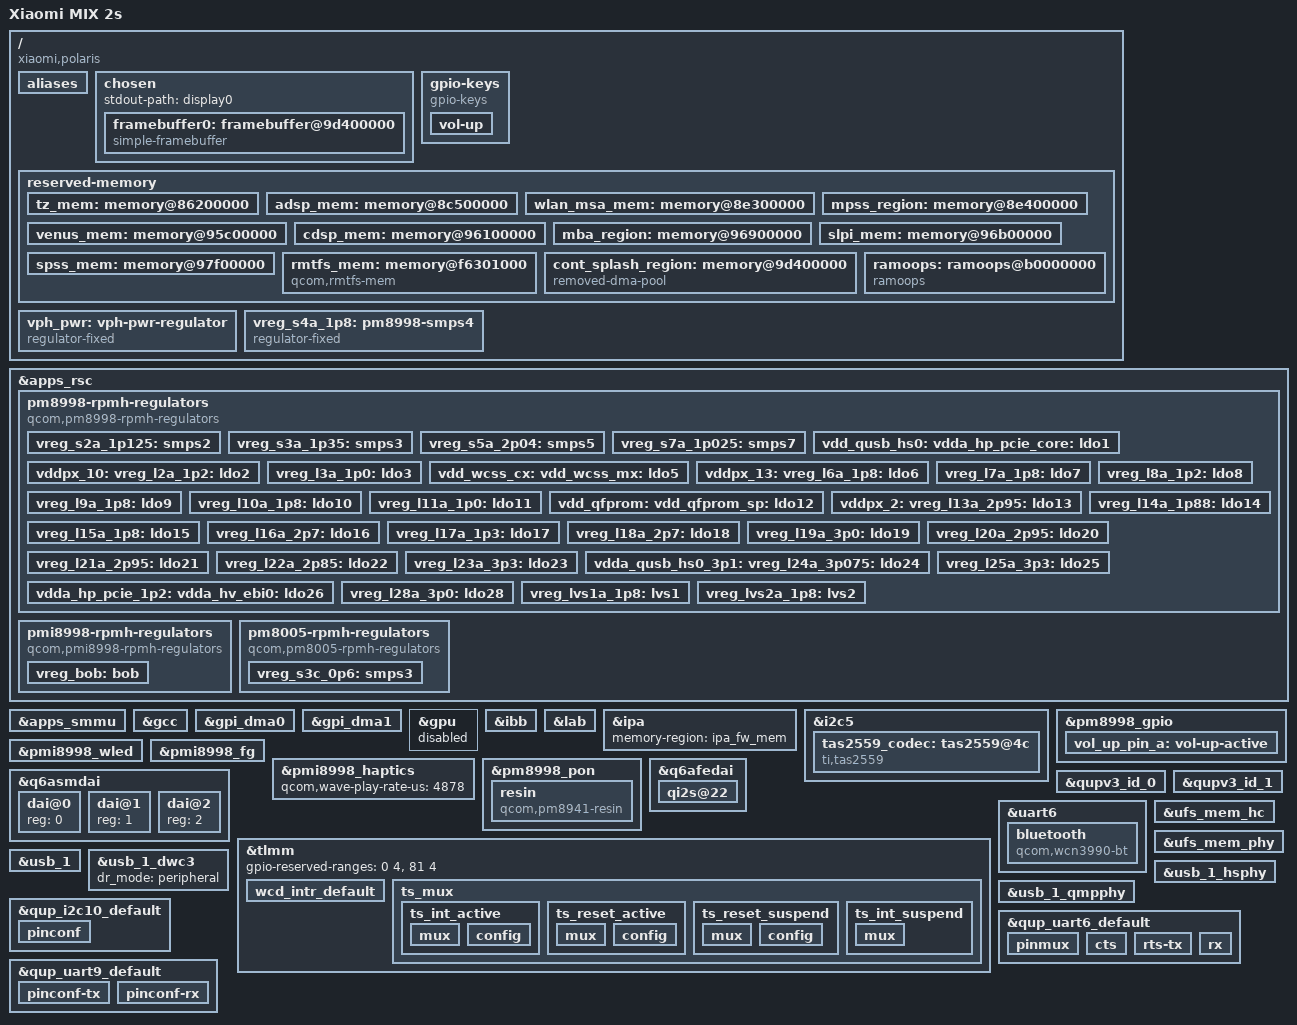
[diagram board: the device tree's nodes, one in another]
// SPDX-License-Identifier: GPL-2.0
/*
	SDM845 Xiaomi MIX 2s (polaris) device tree
*/

/dts-v1/;

#include <dt-bindings/dma/qcom-gpi.h>
#include <dt-bindings/gpio/gpio.h>
#include <dt-bindings/pinctrl/qcom,pmic-gpio.h>
#include <dt-bindings/regulator/qcom,rpmh-regulator.h>
#include <dt-bindings/sound/qcom,q6afe.h>
#include <dt-bindings/sound/qcom,q6asm.h>
#include "sdm845.dtsi"
#include "pm8998.dtsi"
#include "pmi8998.dtsi"

/*
 * Delete following upstream (sdm845.dtsi) reserved
 * memory mappings which are different in this device.
 */
/delete-node/ &tz_mem;
/delete-node/ &adsp_mem;
/delete-node/ &wlan_msa_mem;
/delete-node/ &mpss_region;
/delete-node/ &venus_mem;
/delete-node/ &cdsp_mem;
/delete-node/ &mba_region;
/delete-node/ &slpi_mem;
/delete-node/ &spss_mem;
/delete-node/ &rmtfs_mem;

/delete-node/ &cdsp_pas;
/delete-node/ &dsi0;
/delete-node/ &dsi0_phy;
/delete-node/ &dsi1;
/delete-node/ &dsi1_phy;
/delete-node/ &mdss;
/delete-node/ &mss_pil;
/delete-node/ &sdhc_2;

/delete-node/ &dispcc;

/ {
	model = "Xiaomi MIX 2s";
	compatible = "xiaomi,polaris", "qcom,sdm845";

	/* required for bootloader to select correct board */
	qcom,board-id = <0x2a 0x0>;
	qcom,msm-id = <0x141 0x20001>;

	aliases {
		serial0 = &uart9;
		hsuart0 = &uart6;
	};

	chosen {
		#address-cells = <2>;
		#size-cells = <2>;
		ranges;

		// For simplefb hack
		stdout-path = "display0";
		
		/* hack: use framebuffer setup by bootloader.
		 * the address is taken from the bootloader config (strings xbl.img | grep "Display Reserved")
		 */
		framebuffer0: framebuffer@9d400000 {
			compatible = "simple-framebuffer";
			reg = <0 0x9D400000 0 0x02400000>;
			width = <1080>;
			height = <2160>;
			stride = <(1080 * 4)>;
			format = "a8r8g8b8";
			status = "okay";
		};
	};

	gpio-keys {
		compatible = "gpio-keys";
		autorepeat;

		pinctrl-names = "default";
		pinctrl-0 = <&vol_up_pin_a>;

		vol-up {
			label = "Volume Up";
			linux,code = <KEY_VOLUMEUP>;
			gpios = <&pm8998_gpio 6 GPIO_ACTIVE_LOW>;
		};
	};

	/* Reserved memory changes from downstream */
	reserved-memory {
		tz_mem: memory@86200000 {
			reg = <0 0x86200000 0 0x4900000>;
			no-map;
		};

		adsp_mem: memory@8c500000 {
			reg = <0 0x8c500000 0 0x1e00000>;
			no-map;
		};

		wlan_msa_mem: memory@8e300000 {
			reg = <0 0x8e300000 0 0x100000>;
			no-map;
		};

		mpss_region: memory@8e400000 {
			reg = <0 0x8e400000 0 0x7800000>;
			no-map;
		};

		venus_mem: memory@95c00000 {
			reg = <0 0x95c00000 0 0x500000>;
			no-map;
		};

		cdsp_mem: memory@96100000 {
			reg = <0 0x96100000 0 0x800000>;
			no-map;
		};

		mba_region: memory@96900000 {
			reg = <0 0x96900000 0 0x200000>;
			no-map;
		};

		slpi_mem: memory@96b00000 {
			reg = <0 0x96b00000 0 0x1400000>;
			no-map;
		};

		spss_mem: memory@97f00000 {
			reg = <0 0x97f00000 0 0x100000>;
			no-map;
		};

		rmtfs_mem: memory@f6301000 {
			compatible = "qcom,rmtfs-mem";
			reg = <0 0xf6301000 0 0x200000>;
			no-map;

			qcom,client-id = <1>;
			qcom,vmid = <15>;
		};

		/* hack: bootloader framebuffer */
		cont_splash_region: memory@9d400000 {
			compatible = "removed-dma-pool";
			reg = <0 0x9D400000 0 0x02400000>;
			no-map;
		};

		ramoops: ramoops@b0000000 {
			compatible = "ramoops";
			reg = <0 0xb0000000 0 0x00400000>;
			record-size = <0x40000>; /*256x1024*/
			console-size = <0x40000>;
			ftrace-size = <0x40000>;
			pmsg-size = <0x200000>;
			ecc-size = <0x0>;
		};
	};

	vph_pwr: vph-pwr-regulator {
		compatible = "regulator-fixed";
		regulator-name = "vph_pwr";
		regulator-min-microvolt = <3700000>;
		regulator-max-microvolt = <3700000>;
	};

	/*
	 * Apparently RPMh does not provide support for PM8998 S4 because it
	 * is always-on; model it as a fixed regulator.
	 */
	vreg_s4a_1p8: pm8998-smps4 {
		compatible = "regulator-fixed";
		regulator-name = "vreg_s4a_1p8";

		regulator-min-microvolt = <1800000>;
		regulator-max-microvolt = <1800000>;

		regulator-always-on;
		regulator-boot-on;

		vin-supply = <&vph_pwr>;
	};
};

&apps_rsc {
	pm8998-rpmh-regulators {
		compatible = "qcom,pm8998-rpmh-regulators";
		qcom,pmic-id = "a";

		vdd-s1-supply = <&vph_pwr>;
		vdd-s2-supply = <&vph_pwr>;
		vdd-s3-supply = <&vph_pwr>;
		vdd-s4-supply = <&vph_pwr>;
		vdd-s5-supply = <&vph_pwr>;
		vdd-s6-supply = <&vph_pwr>;
		vdd-s7-supply = <&vph_pwr>;
		vdd-s8-supply = <&vph_pwr>;
		vdd-s9-supply = <&vph_pwr>;
		vdd-s10-supply = <&vph_pwr>;
		vdd-s11-supply = <&vph_pwr>;
		vdd-s12-supply = <&vph_pwr>;
		vdd-s13-supply = <&vph_pwr>;
		vdd-l1-l27-supply = <&vreg_s7a_1p025>;
		vdd-l2-l8-l17-supply = <&vreg_s3a_1p35>;
		vdd-l3-l11-supply = <&vreg_s7a_1p025>;
		vdd-l4-l5-supply = <&vreg_s7a_1p025>;
		vdd-l6-supply = <&vph_pwr>;
		vdd-l7-l12-l14-l15-supply = <&vreg_s5a_2p04>;
		vdd-l9-supply = <&vreg_bob>;
		vdd-l10-l23-l25-supply = <&vreg_bob>;
		vdd-l13-l19-l21-supply = <&vreg_bob>;
		vdd-l16-l28-supply = <&vreg_bob>;
		vdd-l18-l22-supply = <&vreg_bob>;
		vdd-l20-l24-supply = <&vreg_bob>;
		vdd-l26-supply = <&vreg_s3a_1p35>;
		vin-lvs-1-2-supply = <&vreg_s4a_1p8>;

		vreg_s2a_1p125: smps2 {
			regulator-min-microvolt = <1100000>;
			regulator-max-microvolt = <1100000>;
		};

		vreg_s3a_1p35: smps3 {
			regulator-min-microvolt = <1352000>;
			regulator-max-microvolt = <1352000>;
		};

		vreg_s5a_2p04: smps5 {
			regulator-min-microvolt = <1904000>;
			regulator-max-microvolt = <2040000>;
		};

		vreg_s7a_1p025: smps7 {
			regulator-min-microvolt = <900000>;
			regulator-max-microvolt = <1028000>;
		};

		vdd_qusb_hs0:
		vdda_hp_pcie_core:
		vdda_mipi_csi0_0p9:
		vdda_mipi_csi1_0p9:
		vdda_mipi_csi2_0p9:
		vdda_mipi_dsi0_pll:
		vdda_mipi_dsi1_pll:
		vdda_qlink_lv:
		vdda_qlink_lv_ck:
		vdda_qrefs_0p875:
		vdda_pcie_core:
		vdda_pll_cc_ebi01:
		vdda_pll_cc_ebi23:
		vdda_sp_sensor:
		vdda_ufs1_core:
		vdda_ufs2_core:
		vdda_usb1_ss_core:
		vdda_usb2_ss_core:
		vreg_l1a_0p875: ldo1 {
			regulator-min-microvolt = <880000>;
			regulator-max-microvolt = <880000>;
			regulator-initial-mode = <RPMH_REGULATOR_MODE_HPM>;
		};

		vddpx_10:
		vreg_l2a_1p2: ldo2 {
			regulator-min-microvolt = <1200000>;
			regulator-max-microvolt = <1200000>;
			regulator-initial-mode = <RPMH_REGULATOR_MODE_HPM>;
			regulator-always-on;
		};

		vreg_l3a_1p0: ldo3 {
			regulator-min-microvolt = <1000000>;
			regulator-max-microvolt = <1000000>;
			regulator-initial-mode = <RPMH_REGULATOR_MODE_HPM>;
		};

		vdd_wcss_cx:
		vdd_wcss_mx:
		vdda_wcss_pll:
		vreg_l5a_0p8: ldo5 {
			regulator-min-microvolt = <800000>;
			regulator-max-microvolt = <800000>;
			regulator-initial-mode = <RPMH_REGULATOR_MODE_HPM>;
		};

		vddpx_13:
		vreg_l6a_1p8: ldo6 {
			regulator-min-microvolt = <1856000>;
			regulator-max-microvolt = <1856000>;
			regulator-initial-mode = <RPMH_REGULATOR_MODE_HPM>;
		};

		vreg_l7a_1p8: ldo7 {
			regulator-min-microvolt = <1800000>;
			regulator-max-microvolt = <1800000>;
			regulator-initial-mode = <RPMH_REGULATOR_MODE_HPM>;
		};

		vreg_l8a_1p2: ldo8 {
			regulator-min-microvolt = <1200000>;
			regulator-max-microvolt = <1248000>;
			regulator-initial-mode = <RPMH_REGULATOR_MODE_HPM>;
		};

		vreg_l9a_1p8: ldo9 {
			regulator-min-microvolt = <1704000>;
			regulator-max-microvolt = <2928000>;
			regulator-initial-mode = <RPMH_REGULATOR_MODE_HPM>;
		};

		vreg_l10a_1p8: ldo10 {
			regulator-min-microvolt = <1704000>;
			regulator-max-microvolt = <2928000>;
			regulator-initial-mode = <RPMH_REGULATOR_MODE_HPM>;
		};

		vreg_l11a_1p0: ldo11 {
			regulator-min-microvolt = <1000000>;
			regulator-max-microvolt = <1048000>;
			regulator-initial-mode = <RPMH_REGULATOR_MODE_HPM>;
		};

		vdd_qfprom:
		vdd_qfprom_sp:
		vdda_apc1_cs_1p8:
		vdda_gfx_cs_1p8:
		vdda_qrefs_1p8:
		vdda_qusb_hs0_1p8:
		vddpx_11:
		vreg_l12a_1p8: ldo12 {
			regulator-min-microvolt = <1800000>;
			regulator-max-microvolt = <1800000>;
			regulator-initial-mode = <RPMH_REGULATOR_MODE_HPM>;
		};

		vddpx_2:
		vreg_l13a_2p95: ldo13 {
			regulator-min-microvolt = <1800000>;
			regulator-max-microvolt = <2960000>;
			regulator-initial-mode = <RPMH_REGULATOR_MODE_HPM>;
		};

		vreg_l14a_1p88: ldo14 {
			regulator-min-microvolt = <1800000>;
			regulator-max-microvolt = <1800000>;
			regulator-initial-mode = <RPMH_REGULATOR_MODE_HPM>;
		};

		vreg_l15a_1p8: ldo15 {
			regulator-min-microvolt = <1800000>;
			regulator-max-microvolt = <1800000>;
			regulator-initial-mode = <RPMH_REGULATOR_MODE_HPM>;
		};

		vreg_l16a_2p7: ldo16 {
			regulator-min-microvolt = <2704000>;
			regulator-max-microvolt = <2704000>;
			regulator-initial-mode = <RPMH_REGULATOR_MODE_HPM>;
		};

		vreg_l17a_1p3: ldo17 {
			regulator-min-microvolt = <1304000>;
			regulator-max-microvolt = <1304000>;
			regulator-initial-mode = <RPMH_REGULATOR_MODE_HPM>;
		};

		vreg_l18a_2p7: ldo18 {
			regulator-min-microvolt = <2704000>;
			regulator-max-microvolt = <2960000>;
			regulator-initial-mode = <RPMH_REGULATOR_MODE_HPM>;
		};

		vreg_l19a_3p0: ldo19 {
			regulator-min-microvolt = <2856000>;
			regulator-max-microvolt = <3104000>;
			regulator-initial-mode = <RPMH_REGULATOR_MODE_HPM>;
		};

		vreg_l20a_2p95: ldo20 {
			regulator-min-microvolt = <2704000>;
			regulator-max-microvolt = <2960000>;
			regulator-initial-mode = <RPMH_REGULATOR_MODE_HPM>;
		};

		vreg_l21a_2p95: ldo21 {
			regulator-min-microvolt = <2704000>;
			regulator-max-microvolt = <2960000>;
			regulator-initial-mode = <RPMH_REGULATOR_MODE_HPM>;
		};

		vreg_l22a_2p85: ldo22 {
			regulator-min-microvolt = <2864000>;
			regulator-max-microvolt = <3312000>;
			regulator-initial-mode = <RPMH_REGULATOR_MODE_HPM>;
		};

		vreg_l23a_3p3: ldo23 {
			regulator-min-microvolt = <3000000>;
			regulator-max-microvolt = <3312000>;
			regulator-initial-mode = <RPMH_REGULATOR_MODE_HPM>;
		};

		vdda_qusb_hs0_3p1:
		vreg_l24a_3p075: ldo24 {
			regulator-min-microvolt = <3088000>;
			regulator-max-microvolt = <3088000>;
			regulator-initial-mode = <RPMH_REGULATOR_MODE_HPM>;
		};

		vreg_l25a_3p3: ldo25 {
			regulator-min-microvolt = <3300000>;
			regulator-max-microvolt = <3312000>;
			regulator-initial-mode = <RPMH_REGULATOR_MODE_HPM>;
		};

		vdda_hp_pcie_1p2:
		vdda_hv_ebi0:
		vdda_hv_ebi1:
		vdda_hv_ebi2:
		vdda_hv_ebi3:
		vdda_mipi_csi_1p25:
		vdda_mipi_dsi0_1p2:
		vdda_mipi_dsi1_1p2:
		vdda_pcie_1p2:
		vdda_ufs1_1p2:
		vdda_ufs2_1p2:
		vdda_usb1_ss_1p2:
		vdda_usb2_ss_1p2:
		vreg_l26a_1p2: ldo26 {
			regulator-min-microvolt = <1200000>;
			regulator-max-microvolt = <1200000>;
			regulator-initial-mode = <RPMH_REGULATOR_MODE_HPM>;
		};

		vreg_l28a_3p0: ldo28 {
			regulator-min-microvolt = <2856000>;
			regulator-max-microvolt = <3008000>;
			regulator-initial-mode = <RPMH_REGULATOR_MODE_HPM>;
		};

		vreg_lvs1a_1p8: lvs1 {
			regulator-min-microvolt = <1800000>;
			regulator-max-microvolt = <1800000>;
		};

		vreg_lvs2a_1p8: lvs2 {
			regulator-min-microvolt = <1800000>;
			regulator-max-microvolt = <1800000>;
		};
	};

	pmi8998-rpmh-regulators {
		compatible = "qcom,pmi8998-rpmh-regulators";
		qcom,pmic-id = "b";

		vdd-bob-supply = <&vph_pwr>;

		vreg_bob: bob {
			regulator-min-microvolt = <3312000>;
			regulator-max-microvolt = <3600000>;
			regulator-initial-mode = <RPMH_REGULATOR_MODE_AUTO>;
			regulator-allow-bypass;
		};
	};

	pm8005-rpmh-regulators {
		compatible = "qcom,pm8005-rpmh-regulators";
		qcom,pmic-id = "c";

		vdd-s1-supply = <&vph_pwr>;
		vdd-s2-supply = <&vph_pwr>;
		vdd-s3-supply = <&vph_pwr>;
		vdd-s4-supply = <&vph_pwr>;

		vreg_s3c_0p6: smps3 {
			regulator-min-microvolt = <600000>;
			regulator-max-microvolt = <600000>;
		};
	};
};

/*
&apps_rsc {
	pm8998-rpmh-regulators {
		compatible = "qcom,pm8998-rpmh-regulators";
		qcom,pmic-id = "a";

		vreg_l1a_0p875: ldo1 {
			regulator-min-microvolt = <880000>;
			regulator-max-microvolt = <880000>;
			regulator-initial-mode = <RPMH_REGULATOR_MODE_HPM>;
		};

		vreg_l5a_0p8: ldo5 {
			regulator-min-microvolt = <800000>;
			regulator-max-microvolt = <800000>;
			regulator-initial-mode = <RPMH_REGULATOR_MODE_HPM>;
		};

		vreg_l7a_1p8: ldo7 {
			regulator-min-microvolt = <1800000>;
			regulator-max-microvolt = <1800000>;
			regulator-initial-mode = <RPMH_REGULATOR_MODE_HPM>;
		};

		vreg_l12a_1p8: ldo12 {
			regulator-min-microvolt = <1800000>;
			regulator-max-microvolt = <1800000>;
			regulator-initial-mode = <RPMH_REGULATOR_MODE_HPM>;
		};

		vreg_l13a_2p95: ldo13 {
			regulator-min-microvolt = <1800000>;
			regulator-max-microvolt = <2960000>;
			regulator-initial-mode = <RPMH_REGULATOR_MODE_HPM>;
		};

		vreg_l14a_1p8: ldo14 {
			regulator-min-microvolt = <1800000>;
			regulator-max-microvolt = <1800000>;
			regulator-initial-mode = <RPMH_REGULATOR_MODE_HPM>;
			regulator-boot-on;
			regulator-always-on;
		};

		vreg_l17a_1p3: ldo17 {
			regulator-min-microvolt = <1304000>;
			regulator-max-microvolt = <1304000>;
			regulator-initial-mode = <RPMH_REGULATOR_MODE_HPM>;
		};

		vreg_l20a_2p95: ldo20 {
			regulator-min-microvolt = <2960000>;
			regulator-max-microvolt = <2968000>;
			regulator-initial-mode = <RPMH_REGULATOR_MODE_HPM>;
		};

		vreg_l21a_2p95: ldo21 {
			regulator-min-microvolt = <2960000>;
			regulator-max-microvolt = <2968000>;
			regulator-initial-mode = <RPMH_REGULATOR_MODE_HPM>;
		};

		vreg_l24a_3p075: ldo24 {
			regulator-min-microvolt = <3088000>;
			regulator-max-microvolt = <3088000>;
			regulator-initial-mode = <RPMH_REGULATOR_MODE_HPM>;
		};

		vreg_l25a_3p3: ldo25 {
			regulator-min-microvolt = <3300000>;
			regulator-max-microvolt = <3312000>;
			regulator-initial-mode = <RPMH_REGULATOR_MODE_HPM>;
		};

		vreg_l26a_1p2: ldo26 {
			regulator-min-microvolt = <1200000>;
			regulator-max-microvolt = <1200000>;
			regulator-initial-mode = <RPMH_REGULATOR_MODE_HPM>;
			regulator-boot-on;
		};
	};
};
*/

&apps_smmu {
	status = "okay";
};

&gcc {
	protected-clocks = <GCC_QSPI_CORE_CLK>,
			   <GCC_QSPI_CORE_CLK_SRC>,
			   <GCC_QSPI_CNOC_PERIPH_AHB_CLK>,
			   <GCC_LPASS_Q6_AXI_CLK>,
			   <GCC_LPASS_SWAY_CLK>;
};

&gpi_dma0 {
	status = "okay";
};

&gpi_dma1 {
	status = "okay";
};

&gpu {
	status = "disabled";
};

&ibb {
	regulator-min-microvolt = <4600000>;
	regulator-max-microvolt = <6000000>;
	regulator-over-current-protection;
	regulator-pull-down;
	regulator-soft-start;
	qcom,discharge-resistor-kohms = <300>;
};

&lab {
	regulator-min-microvolt = <4600000>;
	regulator-max-microvolt = <6000000>;
	regulator-over-current-protection;
	regulator-pull-down;
	regulator-soft-start;
};

&ipa {
	status = "okay";
	memory-region = <&ipa_fw_mem>;
};


&i2c5 {
	#dma-cells = <3>;
	status="okay";

	dmas = <&gpi_dma0 0 5 QCOM_GPI_I2C>,
		   <&gpi_dma0 1 5 QCOM_GPI_I2C>;
	dma-names = "tx", "rx";

	/*smart PA*/
	tas2559_codec: tas2559@4c{
		#sound-dai-cells = <1>;
		compatible = "ti,tas2559";
		reg = <0x4c>;
		ti,tas2559-reset-gpio = <&tlmm 12 0>;
		ti,tas2560-reset-gpio = <&tlmm 76 0>;
		ti,tas2559-irq-gpio = <&tlmm 11 0>;
		ti,tas2560-irq-gpio = <&tlmm 30 0>;
		ti,tas2559-addr = <0x4c>;
		ti,tas2560-addr = <0x4d>;
		ti,tas2559-channel = <0>; /* 0, left; 1, right */
		ti,tas2560-channel = <1>; /* 0, left; 1, right */
		ti,ycrc-enable = <1>; /* 0, disable; non-zero, enable */
		ti,echo-ref = <0>; /* 0, left channel; 1, right channel; 2, both */
		ti,bit-rate = <16>; /* 16, 20, 24, 32 */
	};
};

&pm8998_gpio {
	vol_up_pin_a: vol-up-active {
		pins = "gpio6";
		function = "normal";
		input-enable;
		bias-pull-up;
		qcom,drive-strength = <PMIC_GPIO_STRENGTH_NO>;
	};
};

&pmi8998_wled {
	status = "okay";
	qcom,current-limit-microamp = <20000>;
	qcom,enabled-strings = <0 1>;
	qcom,num-strings = <2>;
	qcom,switching-freq = <600>;
	qcom,cabc;
};

&pmi8998_fg {
	status = "okay";
	qcom,max-voltage-uv = <4400000>;
	qcom,min-voltage-uv = <3700000>;
	qcom,battery-capacity-ua = <4000000>;
};

&pmi8998_haptics {
	status = "okay";
	// This is the LRA resonant frequency and is device specific
	qcom,wave-play-rate-us = <4878>;
};

&pm8998_pon {
	resin {
		compatible = "qcom,pm8941-resin";
		interrupts = <0x0 0x8 1 IRQ_TYPE_EDGE_BOTH>;
		debounce = <15625>;
		bias-pull-up;
		linux,code = <KEY_VOLUMEDOWN>;
	};
};

/* QUAT I2S Uses 1 I2S SD Line for audio on TAS2559/60 amplifiers */
&q6afedai {
	qi2s@22 {
		reg = <22>;
		qcom,sd-lines = <0>;
	};
};

&q6asmdai {
	dai@0 {
		reg = <0>;
	};

	dai@1 {
		reg = <1>;
	};

	dai@2 {
		reg = <2>;
	};
};

&qupv3_id_0 {
	status = "okay";
};

&qupv3_id_1 {
	status = "okay";
};

&tlmm {
	gpio-reserved-ranges = <0 4>, <81 4>;

	wcd_intr_default: wcd_intr_default {
		pins = <54>;
		function = "gpio";

		input-enable;
		bias-pull-down;
		drive-strength = <2>;
	};
};

&uart6 {
	status = "okay";

	bluetooth {
		compatible = "qcom,wcn3990-bt";

		vddio-supply = <&vreg_s4a_1p8>;
		vddxo-supply = <&vreg_l7a_1p8>;
		vddrf-supply = <&vreg_l17a_1p3>;
		vddch0-supply = <&vreg_l25a_3p3>;
		max-speed = <3200000>;
	};
};

&ufs_mem_hc {
	status = "okay";

	reset-gpios = <&tlmm 150 GPIO_ACTIVE_LOW>;

	vcc-supply = <&vreg_l20a_2p95>;
	vcc-max-microamp = <800000>;
};

&ufs_mem_phy {
	status = "okay";

	vdda-phy-supply = <&vreg_l1a_0p875>;
	vdda-pll-supply = <&vreg_l26a_1p2>;
};

&usb_1 {
	status = "okay";
};

&usb_1_dwc3 {
	/* Until we have Type C hooked up we'll force this as peripheral. */
	dr_mode = "peripheral";
};

&usb_1_hsphy {
	status = "okay";

	vdd-supply = <&vdda_usb1_ss_core>;
	vdda-pll-supply = <&vdda_qusb_hs0_1p8>;
	vdda-phy-dpdm-supply = <&vdda_qusb_hs0_3p1>;

	qcom,imp-res-offset-value = <8>;
	qcom,hstx-trim-value = <QUSB2_V2_HSTX_TRIM_21_6_MA>;
	qcom,preemphasis-level = <QUSB2_V2_PREEMPHASIS_5_PERCENT>;
	qcom,preemphasis-width = <QUSB2_V2_PREEMPHASIS_WIDTH_HALF_BIT>;
};

&usb_1_qmpphy {
	status = "okay";

	vdda-phy-supply = <&vdda_usb1_ss_1p2>;
	vdda-pll-supply = <&vdda_usb1_ss_core>;
};

/*
&usb_1_hsphy {
	status = "okay";

	vdd-supply = <&vreg_l1a_0p875>;
	vdda-pll-supply = <&vreg_l12a_1p8>;
	vdda-phy-dpdm-supply = <&vreg_l24a_3p075>;

	qcom,imp-res-offset-value = <8>;
	qcom,hstx-trim-value = <QUSB2_V2_HSTX_TRIM_21_6_MA>;
	qcom,preemphasis-level = <QUSB2_V2_PREEMPHASIS_5_PERCENT>;
	qcom,preemphasis-width = <QUSB2_V2_PREEMPHASIS_WIDTH_HALF_BIT>;
};

&usb_1_qmpphy {
	status = "okay";

	vdda-phy-supply = <&vreg_l26a_1p2>;
	vdda-pll-supply = <&vreg_l1a_0p875>;
};
*/

/* PINCTRL - additions to nodes defined in sdm845.dtsi */

&qup_uart6_default {
	pinmux {
		pins = "gpio45", "gpio46", "gpio47", "gpio48";
		function = "qup6";
	};

	cts {
		pins = "gpio45";
		bias-disable;
	};

	rts-tx {
		pins = "gpio46", "gpio47";
		drive-strength = <2>;
		bias-disable;
	};

	rx {
		pins = "gpio48";
		bias-pull-up;
	};
};

&qup_i2c10_default {
	pinconf {
		pins = "gpio55", "gpio56";
		drive-strength = <2>;
		bias-disable;
	};
};

&qup_uart9_default {
	pinconf-tx {
		pins = "gpio4";
		drive-strength = <2>;
		bias-disable;
	};

	pinconf-rx {
		pins = "gpio5";
		drive-strength = <2>;
		bias-pull-up;
	};
};

&tlmm {
	ts_mux {

		ts_int_active: ts_int_active {
			mux {
				pins = "gpio31";
				function = "gpio";
			};

			config {
				pins = "gpio31";
				drive-strength = <16>;
				bias-pull-down;
				input-enable;
			};
		};

		ts_reset_active: ts_reset_active {
			mux {
				pins = "gpio32";
				function = "gpio";
			};

			config {
				pins = "gpio32";
				drive-strength = <16>;
				output-high;
			};
		};

		ts_reset_suspend: ts_reset_suspend {
			mux {
				pins = "gpio32";
				function = "gpio";
			};

			config {
				pins = "gpio32";
				drive-strength = <2>;
				bias-disable;
				output-low;
			};
		};

		ts_int_suspend: ts_int_suspend {
			mux {
				pins = "gpio31";
				function = "gpio";
			};

		};
	};
};

